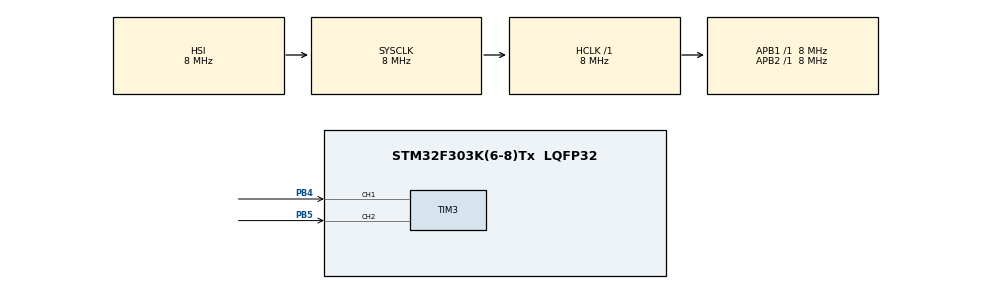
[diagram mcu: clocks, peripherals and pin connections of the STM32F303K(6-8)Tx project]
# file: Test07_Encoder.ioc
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Mcu.Family=STM32F3
Mcu.Name=STM32F303K(6-8)Tx
Mcu.Package=LQFP32
NVIC.PriorityGroup=NVIC_PRIORITYGROUP_4
PB4.Signal=S_TIM3_CH1
PB5.Signal=S_TIM3_CH2
ProjectManager.HeapSize=0x200
ProjectManager.StackSize=0x400
ProjectManager.TargetToolchain=SW4STM32
RCC.AHBFreq_Value=8000000
RCC.APB1Freq_Value=8000000
RCC.APB2Freq_Value=8000000
RCC.CortexFreq_Value=8000000
RCC.HSE_VALUE=8000000
RCC.HSI_VALUE=8000000
RCC.SYSCLKFreq_VALUE=8000000
SH.S_TIM3_CH1.0=TIM3_CH1,Encoder_Interface
SH.S_TIM3_CH2.0=TIM3_CH2,Encoder_Interface
board=Test07_Encoder

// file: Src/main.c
/**
  ******************************************************************************
  * File Name          : main.c
  * Description        : Main program body
  ******************************************************************************
  *
  * COPYRIGHT(c) 2017 STMicroelectronics
  *
  * Redistribution and use in source and binary forms, with or without modification,
  * are permitted provided that the following conditions are met:
  *   1. Redistributions of source code must retain the above copyright notice,
  *      this list of conditions and the following disclaimer.
  *   2. Redistributions in binary form must reproduce the above copyright notice,
  *      this list of conditions and the following disclaimer in the documentation
  *      and/or other materials provided with the distribution.
  *   3. Neither the name of STMicroelectronics nor the names of its contributors
  *      may be used to endorse or promote products derived from this software
  *      without specific prior written permission.
  *
  * THIS SOFTWARE IS PROVIDED BY THE COPYRIGHT HOLDERS AND CONTRIBUTORS "AS IS"
  * AND ANY EXPRESS OR IMPLIED WARRANTIES, INCLUDING, BUT NOT LIMITED TO, THE
  * IMPLIED WARRANTIES OF MERCHANTABILITY AND FITNESS FOR A PARTICULAR PURPOSE ARE
  * DISCLAIMED. IN NO EVENT SHALL THE COPYRIGHT HOLDER OR CONTRIBUTORS BE LIABLE
  * FOR ANY DIRECT, INDIRECT, INCIDENTAL, SPECIAL, EXEMPLARY, OR CONSEQUENTIAL
  * DAMAGES (INCLUDING, BUT NOT LIMITED TO, PROCUREMENT OF SUBSTITUTE GOODS OR
  * SERVICES; LOSS OF USE, DATA, OR PROFITS; OR BUSINESS INTERRUPTION) HOWEVER
  * CAUSED AND ON ANY THEORY OF LIABILITY, WHETHER IN CONTRACT, STRICT LIABILITY,
  * OR TORT (INCLUDING NEGLIGENCE OR OTHERWISE) ARISING IN ANY WAY OUT OF THE USE
  * OF THIS SOFTWARE, EVEN IF ADVISED OF THE POSSIBILITY OF SUCH DAMAGE.
  *
  ******************************************************************************
  */
#include "main.h"
#include "stm32f3xx_hal.h"

TIM_HandleTypeDef htim3;

/* USER CODE BEGIN PV */
/* Private variables ---------------------------------------------------------*/

/* USER CODE END PV */

void SystemClock_Config(void);
void Error_Handler(void);
static void MX_GPIO_Init(void);
static void MX_TIM3_Init(void);

/* USER CODE BEGIN PFP */
/* Private function prototypes -----------------------------------------------*/

/* USER CODE END PFP */

int main(void)
{

  /* USER CODE BEGIN 1 */
	uint8_t i=0,j=0;
  /* USER CODE END 1 */

  /* MCU Configuration----------------------------------------------------------*/

  /* Reset of all peripherals, Initializes the Flash interface and the Systick. */
  HAL_Init();

  /* Configure the system clock */
  SystemClock_Config();

  /* Initialize all configured peripherals */
  MX_GPIO_Init();
  MX_TIM3_Init();

  /* USER CODE BEGIN 2 */
	HAL_TIM_Encoder_Start(&htim3,TIM_CHANNEL_ALL);
  /* USER CODE END 2 */

  /* Infinite loop */
  while (1)
  {

		i = TIM3->CNT;

		if( (i-j) > 0 ){
			HAL_GPIO_WritePin(LED1_GPIO_Port,LED1_Pin,GPIO_PIN_SET);
		}else{
			HAL_GPIO_WritePin(LED1_GPIO_Port,LED1_Pin,GPIO_PIN_RESET);
		}
		if( (i-j) < 0 ){
			HAL_GPIO_WritePin(LED1_GPIO_Port,LED1_Pin,GPIO_PIN_SET);
		}else{
			HAL_GPIO_WritePin(LED1_GPIO_Port,LED1_Pin,GPIO_PIN_RESET);
		}

		j = i;

  }

}

/** System Clock Configuration
*/
void SystemClock_Config(void)
{

  RCC_OscInitTypeDef RCC_OscInitStruct;
  RCC_ClkInitTypeDef RCC_ClkInitStruct;

    /**Initializes the CPU, AHB and APB busses clocks
    */
  RCC_OscInitStruct.OscillatorType = RCC_OSCILLATORTYPE_HSI;
  RCC_OscInitStruct.HSIState = RCC_HSI_ON;
  RCC_OscInitStruct.HSICalibrationValue = 16;
  RCC_OscInitStruct.PLL.PLLState = RCC_PLL_NONE;
  if (HAL_RCC_OscConfig(&RCC_OscInitStruct) != HAL_OK)
  {
    Error_Handler();
  }

    /**Initializes the CPU, AHB and APB busses clocks
    */
  RCC_ClkInitStruct.ClockType = RCC_CLOCKTYPE_HCLK|RCC_CLOCKTYPE_SYSCLK
                              |RCC_CLOCKTYPE_PCLK1|RCC_CLOCKTYPE_PCLK2;
  RCC_ClkInitStruct.SYSCLKSource = RCC_SYSCLKSOURCE_HSI;
  RCC_ClkInitStruct.AHBCLKDivider = RCC_SYSCLK_DIV1;
  RCC_ClkInitStruct.APB1CLKDivider = RCC_HCLK_DIV1;
  RCC_ClkInitStruct.APB2CLKDivider = RCC_HCLK_DIV1;

  if (HAL_RCC_ClockConfig(&RCC_ClkInitStruct, FLASH_LATENCY_0) != HAL_OK)
  {
    Error_Handler();
  }

    /**Configure the Systick interrupt time
    */
  HAL_SYSTICK_Config(HAL_RCC_GetHCLKFreq()/1000);

    /**Configure the Systick
    */
  HAL_SYSTICK_CLKSourceConfig(SYSTICK_CLKSOURCE_HCLK);

  /* SysTick_IRQn interrupt configuration */
  HAL_NVIC_SetPriority(SysTick_IRQn, 0, 0);
}

/* TIM3 init function */
static void MX_TIM3_Init(void)
{

  TIM_Encoder_InitTypeDef sConfig;
  TIM_MasterConfigTypeDef sMasterConfig;

  htim3.Instance = TIM3;
  htim3.Init.Prescaler = 0;
  htim3.Init.CounterMode = TIM_COUNTERMODE_UP;
  htim3.Init.Period = 65535;
  htim3.Init.ClockDivision = TIM_CLOCKDIVISION_DIV1;
  sConfig.EncoderMode = TIM_ENCODERMODE_TI12;
  sConfig.IC1Polarity = TIM_ICPOLARITY_RISING;
  sConfig.IC1Selection = TIM_ICSELECTION_DIRECTTI;
  sConfig.IC1Prescaler = TIM_ICPSC_DIV1;
  sConfig.IC1Filter = 0;
  sConfig.IC2Polarity = TIM_ICPOLARITY_RISING;
  sConfig.IC2Selection = TIM_ICSELECTION_DIRECTTI;
  sConfig.IC2Prescaler = TIM_ICPSC_DIV1;
  sConfig.IC2Filter = 0;
  if (HAL_TIM_Encoder_Init(&htim3, &sConfig) != HAL_OK)
  {
    Error_Handler();
  }

  sMasterConfig.MasterOutputTrigger = TIM_TRGO_RESET;
  sMasterConfig.MasterSlaveMode = TIM_MASTERSLAVEMODE_DISABLE;
  if (HAL_TIMEx_MasterConfigSynchronization(&htim3, &sMasterConfig) != HAL_OK)
  {
    Error_Handler();
  }

}

/** Pinout Configuration
*/
static void MX_GPIO_Init(void)
{

  GPIO_InitTypeDef GPIO_InitStruct;

  /* GPIO Ports Clock Enable */
  __HAL_RCC_GPIOB_CLK_ENABLE();

  /*Configure GPIO pin Output Level */
  HAL_GPIO_WritePin(GPIOB, LED1_Pin, GPIO_PIN_RESET);

  /*Configure GPIO pins : LED1_Pin */
  GPIO_InitStruct.Pin = LED1_Pin;
  GPIO_InitStruct.Mode = GPIO_MODE_OUTPUT_PP;
  GPIO_InitStruct.Pull = GPIO_NOPULL;
  GPIO_InitStruct.Speed = GPIO_SPEED_FREQ_LOW;
  HAL_GPIO_Init(GPIOB, &GPIO_InitStruct);
}

void Error_Handler(void)
{
  /* USER CODE BEGIN Error_Handler */
  /* User can add his own implementation to report the HAL error return state */
  while(1)
  {
		HAL_GPIO_WritePin(LED1_GPIO_Port,LED1_Pin,GPIO_PIN_SET);
		HAL_Delay(200);
		HAL_GPIO_WritePin(LED1_GPIO_Port,LED1_Pin,GPIO_PIN_RESET);
		HAL_Delay(50);
  }
  /* USER CODE END Error_Handler */
}

/************************ (C) COPYRIGHT STMicroelectronics *****END OF FILE****/
